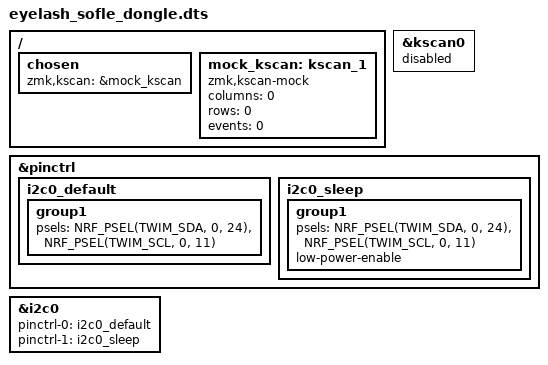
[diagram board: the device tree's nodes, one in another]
/*
*
* Copyright (c) 2021 Darryl deHaan
* SPDX-License-Identifier: MIT
*
*/

#include "eyelash_sofle.dtsi"

&kscan0 {
    status = "disabled";
};

&pinctrl {
    i2c0_default: i2c0_default {
        group1 {
            psels = <NRF_PSEL(TWIM_SDA, 0, 24)>,
                    <NRF_PSEL(TWIM_SCL, 0, 11)>;
        };
    };

    i2c0_sleep: i2c0_sleep {
        group1 {
            psels = <NRF_PSEL(TWIM_SDA, 0, 24)>,
                    <NRF_PSEL(TWIM_SCL, 0, 11)>;
            low-power-enable;
        };
    };
};

pro_micro_i2c: &i2c0 {
    status = "okay";
    pinctrl-0 = <&i2c0_default>;
    pinctrl-1 = <&i2c0_sleep>;
    pinctrl-names = "default", "sleep";
};

/{
    chosen {
        zmk,kscan = &mock_kscan;
    };
    mock_kscan: kscan_1 {
        compatible = "zmk,kscan-mock";
        columns = <0>;
        rows = <0>;
        events = <0>;
    };
};

